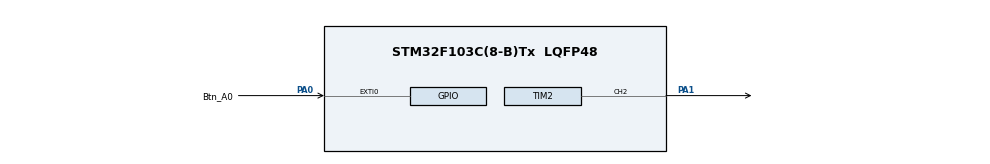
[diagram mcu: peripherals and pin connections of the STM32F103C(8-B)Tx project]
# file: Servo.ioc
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Mcu.Family=STM32F1
Mcu.Name=STM32F103C(8-B)Tx
Mcu.Package=LQFP48
NVIC.EXTI0_IRQn=true\:1\:0\:true\:false\:true\:true\:true\:true
NVIC.PriorityGroup=NVIC_PRIORITYGROUP_4
PA0-WKUP.GPIO_Label=Btn_A0
PA0-WKUP.GPIO_ModeDefaultEXTI=GPIO_MODE_IT_FALLING
PA0-WKUP.GPIO_PuPd=GPIO_PULLUP
PA0-WKUP.Signal=GPXTI0
PA1.Signal=S_TIM2_CH2
PA13.Mode=Serial_Wire
PA13.Signal=SYS_JTMS-SWDIO
PA14.Mode=Serial_Wire
PA14.Signal=SYS_JTCK-SWCLK
ProjectManager.HeapSize=0x200
ProjectManager.StackSize=0x400
ProjectManager.TargetToolchain=MDK-ARM V5
RCC.APB1Freq_Value=8000000
RCC.APB2Freq_Value=8000000
SH.S_TIM2_CH2.0=TIM2_CH2,PWM Generation2 CH2
TIM2.Channel-PWM\ Generation2\ CH2=TIM_CHANNEL_2
TIM2.Period=200-1
TIM2.Prescaler=800-1
VP_TIM2_VS_ClockSourceINT.Mode=Internal
board=custom

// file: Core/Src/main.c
/* USER CODE BEGIN Header */
/**
  ******************************************************************************
  * @file           : main.c
  * @brief          : Main program body
  ******************************************************************************
  * @attention
  *
  * Copyright (c) 2023 STMicroelectronics.
  * All rights reserved.
  *
  * This software is licensed under terms that can be found in the LICENSE file
  * in the root directory of this software component.
  * If no LICENSE file comes with this software, it is provided AS-IS.
  *
  ******************************************************************************
  */
/* USER CODE END Header */
#include "main.h"

TIM_HandleTypeDef htim2;

/* USER CODE BEGIN PV */
uint8_t count=0;
uint16_t value;
/* USER CODE END PV */

void SystemClock_Config(void);
static void MX_GPIO_Init(void);
static void MX_TIM2_Init(void);
/* USER CODE BEGIN PFP */
long map(long x, long in_min, long in_max, long out_min, long out_max) {
  return (x - in_min) * (out_max - out_min) / (in_max - in_min) + out_min;
}

void HAL_GPIO_EXTI_Callback(uint16_t GPIO_Pin)
{
	HAL_Delay(50);
	if (HAL_GPIO_ReadPin(GPIOA,GPIO_PIN_0)==0) {
		count++;
	}
	if (count>3)
	{
		count =0;
	}
	switch (count){
			case 1:
				value=map(-90,-90,90,100,200);
				__HAL_TIM_SET_COMPARE(&htim2,TIM_CHANNEL_2,value);
				HAL_Delay(3);
				break;
			case 2:
				value=map(90,-90,90,100,200);
				__HAL_TIM_SET_COMPARE(&htim2,TIM_CHANNEL_2,value);
				HAL_Delay(3);
				break;
			case 3:
				value=map(0,-90,90,100,200);
				__HAL_TIM_SET_COMPARE(&htim2,TIM_CHANNEL_2,value);
				HAL_Delay(3);
				break;
		}
}

/* USER CODE END PFP */

int main(void)
{

  /* MCU Configuration--------------------------------------------------------*/

  /* Reset of all peripherals, Initializes the Flash interface and the Systick. */
  HAL_Init();

  /* Configure the system clock */
  SystemClock_Config();

  /* Initialize all configured peripherals */
  MX_GPIO_Init();
  MX_TIM2_Init();
  /* USER CODE BEGIN 2 */
	HAL_TIM_PWM_Start(&htim2,TIM_CHANNEL_2);
  /* USER CODE END 2 */

  /* Infinite loop */
  while (1)
  {

  }
}

void SystemClock_Config(void)
{
  RCC_OscInitTypeDef RCC_OscInitStruct = {0};
  RCC_ClkInitTypeDef RCC_ClkInitStruct = {0};

  /** Initializes the RCC Oscillators according to the specified parameters
  * in the RCC_OscInitTypeDef structure.
  */
  RCC_OscInitStruct.OscillatorType = RCC_OSCILLATORTYPE_HSI;
  RCC_OscInitStruct.HSIState = RCC_HSI_ON;
  RCC_OscInitStruct.HSICalibrationValue = RCC_HSICALIBRATION_DEFAULT;
  RCC_OscInitStruct.PLL.PLLState = RCC_PLL_NONE;
  if (HAL_RCC_OscConfig(&RCC_OscInitStruct) != HAL_OK)
  {
    Error_Handler();
  }

  /** Initializes the CPU, AHB and APB buses clocks
  */
  RCC_ClkInitStruct.ClockType = RCC_CLOCKTYPE_HCLK|RCC_CLOCKTYPE_SYSCLK
                              |RCC_CLOCKTYPE_PCLK1|RCC_CLOCKTYPE_PCLK2;
  RCC_ClkInitStruct.SYSCLKSource = RCC_SYSCLKSOURCE_HSI;
  RCC_ClkInitStruct.AHBCLKDivider = RCC_SYSCLK_DIV1;
  RCC_ClkInitStruct.APB1CLKDivider = RCC_HCLK_DIV1;
  RCC_ClkInitStruct.APB2CLKDivider = RCC_HCLK_DIV1;

  if (HAL_RCC_ClockConfig(&RCC_ClkInitStruct, FLASH_LATENCY_0) != HAL_OK)
  {
    Error_Handler();
  }
}

static void MX_TIM2_Init(void)
{

  TIM_ClockConfigTypeDef sClockSourceConfig = {0};
  TIM_MasterConfigTypeDef sMasterConfig = {0};
  TIM_OC_InitTypeDef sConfigOC = {0};

  htim2.Instance = TIM2;
  htim2.Init.Prescaler = 80-1;
  htim2.Init.CounterMode = TIM_COUNTERMODE_UP;
  htim2.Init.Period = 2000-1;
  htim2.Init.ClockDivision = TIM_CLOCKDIVISION_DIV1;
  htim2.Init.AutoReloadPreload = TIM_AUTORELOAD_PRELOAD_DISABLE;
  if (HAL_TIM_Base_Init(&htim2) != HAL_OK)
  {
    Error_Handler();
  }
  sClockSourceConfig.ClockSource = TIM_CLOCKSOURCE_INTERNAL;
  if (HAL_TIM_ConfigClockSource(&htim2, &sClockSourceConfig) != HAL_OK)
  {
    Error_Handler();
  }
  if (HAL_TIM_PWM_Init(&htim2) != HAL_OK)
  {
    Error_Handler();
  }
  sMasterConfig.MasterOutputTrigger = TIM_TRGO_RESET;
  sMasterConfig.MasterSlaveMode = TIM_MASTERSLAVEMODE_DISABLE;
  if (HAL_TIMEx_MasterConfigSynchronization(&htim2, &sMasterConfig) != HAL_OK)
  {
    Error_Handler();
  }
  sConfigOC.OCMode = TIM_OCMODE_PWM1;
  sConfigOC.Pulse = 150;
  sConfigOC.OCPolarity = TIM_OCPOLARITY_HIGH;
  sConfigOC.OCFastMode = TIM_OCFAST_DISABLE;
  if (HAL_TIM_PWM_ConfigChannel(&htim2, &sConfigOC, TIM_CHANNEL_2) != HAL_OK)
  {
    Error_Handler();
  }
  HAL_TIM_MspPostInit(&htim2);

}

static void MX_GPIO_Init(void)
{
  GPIO_InitTypeDef GPIO_InitStruct = {0};

  /* GPIO Ports Clock Enable */
  __HAL_RCC_GPIOA_CLK_ENABLE();

  /*Configure GPIO pin : PA0 */
  GPIO_InitStruct.Pin = GPIO_PIN_0;
  GPIO_InitStruct.Mode = GPIO_MODE_IT_FALLING;
  GPIO_InitStruct.Pull = GPIO_PULLUP;
  HAL_GPIO_Init(GPIOA, &GPIO_InitStruct);

  /* EXTI interrupt init*/
  HAL_NVIC_SetPriority(EXTI0_IRQn, 1, 0);
  HAL_NVIC_EnableIRQ(EXTI0_IRQn);

}

void Error_Handler(void)
{
  __disable_irq();
  while (1)
  {
  }
}
